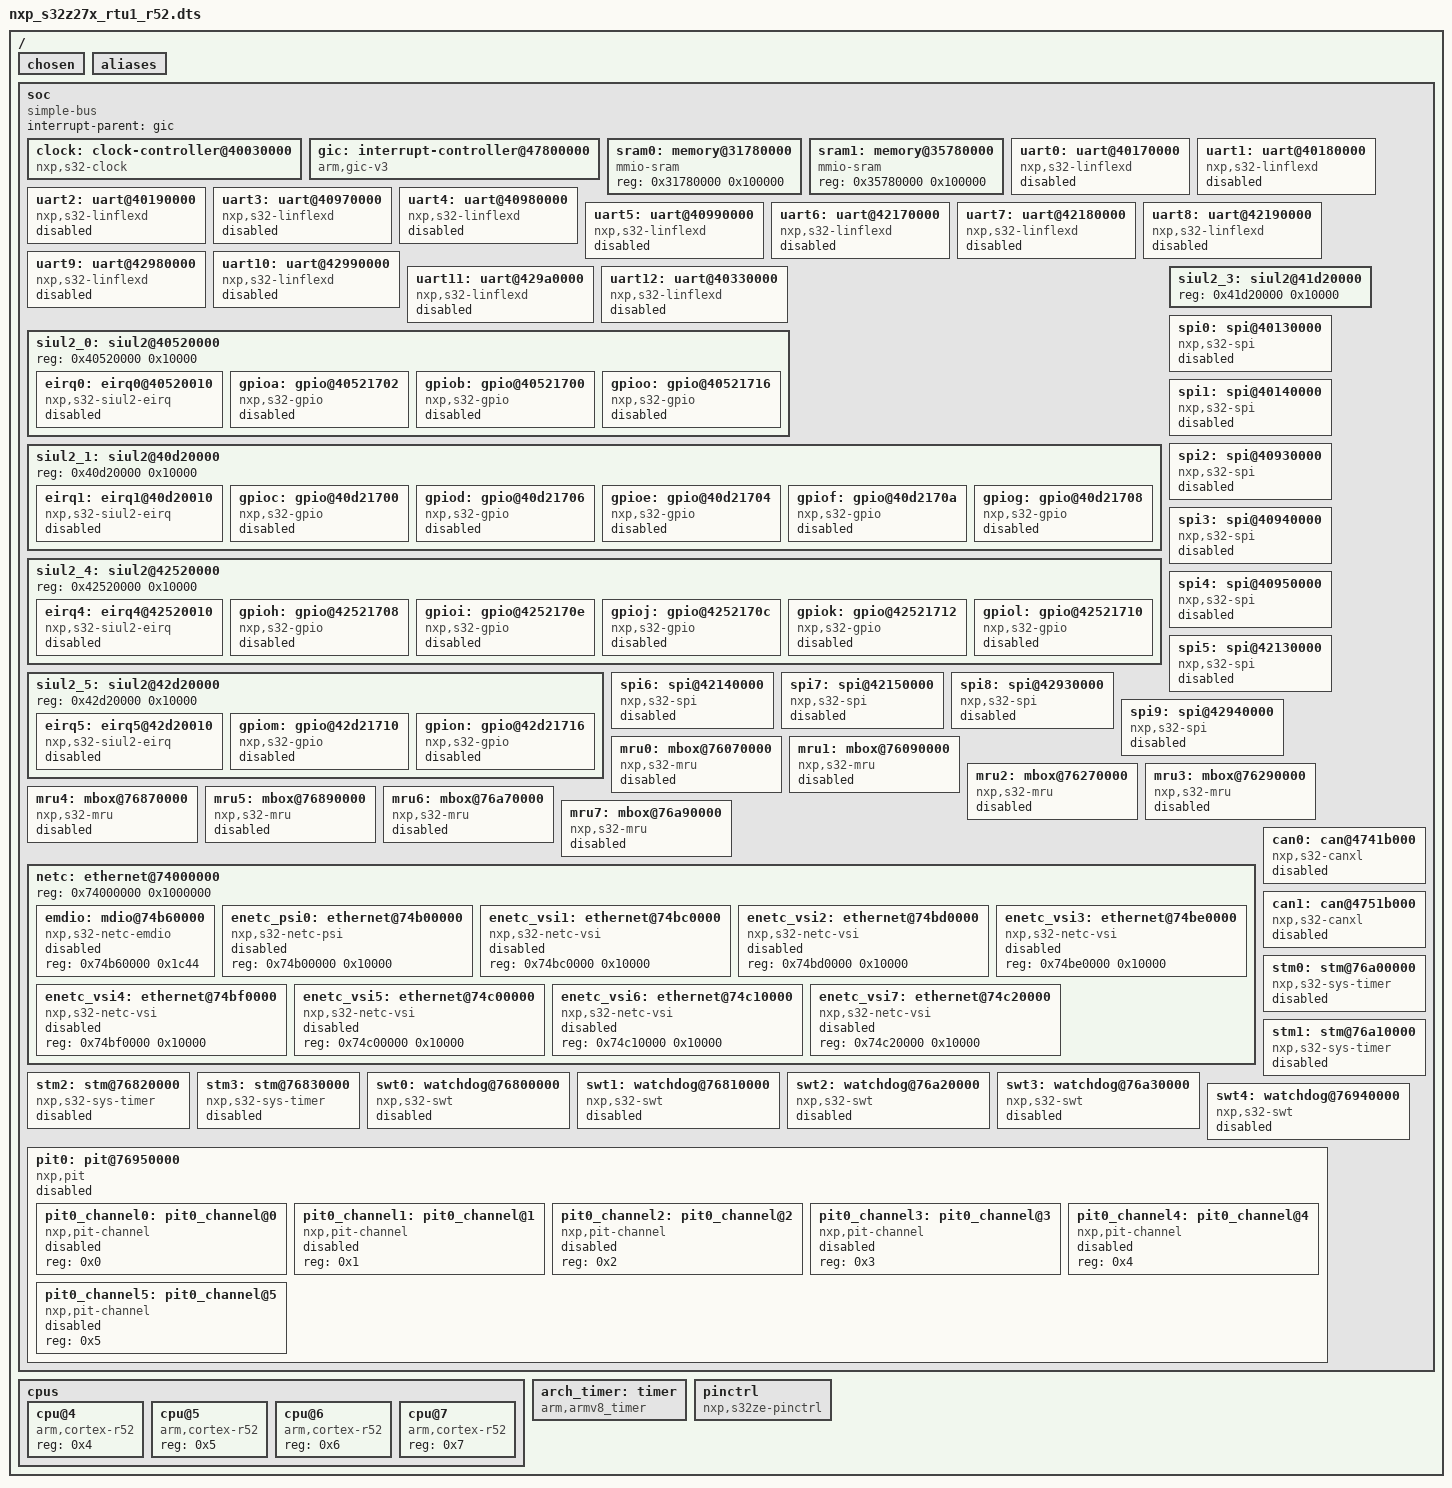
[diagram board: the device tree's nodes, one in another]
/dts-v1/;

/ {
	#address-cells = < 0x1 >;
	#size-cells = < 0x1 >;
	chosen {
	};
	aliases {
	};
	soc {
		#address-cells = < 0x1 >;
		#size-cells = < 0x1 >;
		compatible = "simple-bus";
		ranges;
		interrupt-parent = < &gic >;
		clock: clock-controller@40030000 {
			compatible = "nxp,s32-clock";
			reg = < 0x40030000 0x10000 >, < 0x40200000 0x10000 >, < 0x40210000 0x10000 >, < 0x40220000 0x10000 >, < 0x40260000 0x10000 >, < 0x40270000 0x10000 >, < 0x40830000 0x10000 >, < 0x41030000 0x10000 >, < 0x41830000 0x10000 >, < 0x42030000 0x10000 >, < 0x42830000 0x10000 >, < 0x44030000 0x10000 >, < 0x440a0000 0x10000 >;
			#clock-cells = < 0x1 >;
			status = "okay";
			phandle = < 0x6 >;
		};
		gic: interrupt-controller@47800000 {
			compatible = "arm,gic-v3", "arm,gic";
			reg = < 0x47800000 0x10000 >, < 0x47900000 0x80000 >;
			interrupt-controller;
			#interrupt-cells = < 0x4 >;
			status = "okay";
			phandle = < 0x1 >;
		};
		sram0: memory@31780000 {
			compatible = "mmio-sram";
			reg = < 0x31780000 0x100000 >;
		};
		sram1: memory@35780000 {
			compatible = "mmio-sram";
			reg = < 0x35780000 0x100000 >;
		};
		uart0: uart@40170000 {
			compatible = "nxp,s32-linflexd";
			reg = < 0x40170000 0x1000 >;
			interrupts = < 0x0 0xd4 0x2 0xa0 >;
			status = "disabled";
		};
		uart1: uart@40180000 {
			compatible = "nxp,s32-linflexd";
			reg = < 0x40180000 0x1000 >;
			interrupts = < 0x0 0xd5 0x2 0xa0 >;
			status = "disabled";
		};
		uart2: uart@40190000 {
			compatible = "nxp,s32-linflexd";
			reg = < 0x40190000 0x1000 >;
			interrupts = < 0x0 0xd6 0x2 0xa0 >;
			status = "disabled";
		};
		uart3: uart@40970000 {
			compatible = "nxp,s32-linflexd";
			reg = < 0x40970000 0x1000 >;
			interrupts = < 0x0 0xd7 0x2 0xa0 >;
			status = "disabled";
		};
		uart4: uart@40980000 {
			compatible = "nxp,s32-linflexd";
			reg = < 0x40980000 0x1000 >;
			interrupts = < 0x0 0xd8 0x2 0xa0 >;
			status = "disabled";
		};
		uart5: uart@40990000 {
			compatible = "nxp,s32-linflexd";
			reg = < 0x40990000 0x1000 >;
			interrupts = < 0x0 0xd9 0x2 0xa0 >;
			status = "disabled";
		};
		uart6: uart@42170000 {
			compatible = "nxp,s32-linflexd";
			reg = < 0x42170000 0x1000 >;
			interrupts = < 0x0 0xda 0x2 0xa0 >;
			status = "disabled";
		};
		uart7: uart@42180000 {
			compatible = "nxp,s32-linflexd";
			reg = < 0x42180000 0x1000 >;
			interrupts = < 0x0 0xdb 0x2 0xa0 >;
			status = "disabled";
		};
		uart8: uart@42190000 {
			compatible = "nxp,s32-linflexd";
			reg = < 0x42190000 0x1000 >;
			interrupts = < 0x0 0xdc 0x2 0xa0 >;
			status = "disabled";
		};
		uart9: uart@42980000 {
			compatible = "nxp,s32-linflexd";
			reg = < 0x42980000 0x1000 >;
			interrupts = < 0x0 0xdd 0x2 0xa0 >;
			status = "disabled";
		};
		uart10: uart@42990000 {
			compatible = "nxp,s32-linflexd";
			reg = < 0x42990000 0x1000 >;
			interrupts = < 0x0 0xde 0x2 0xa0 >;
			status = "disabled";
		};
		uart11: uart@429a0000 {
			compatible = "nxp,s32-linflexd";
			reg = < 0x429a0000 0x1000 >;
			interrupts = < 0x0 0xdf 0x2 0xa0 >;
			status = "disabled";
		};
		uart12: uart@40330000 {
			compatible = "nxp,s32-linflexd";
			reg = < 0x40330000 0x1000 >;
			interrupts = < 0x0 0xcd 0x2 0xa0 >;
			status = "disabled";
		};
		siul2_0: siul2@40520000 {
			reg = < 0x40520000 0x10000 >;
			#address-cells = < 0x1 >;
			#size-cells = < 0x1 >;
			eirq0: eirq0@40520010 {
				compatible = "nxp,s32-siul2-eirq";
				reg = < 0x40520010 0x4 >, < 0x40520018 0x4 >;
				reg-names = "disr0", "direr0";
				interrupts = < 0x0 0x202 0x2 0xa0 >;
				interrupt-controller;
				#interrupt-cells = < 0x2 >;
				status = "disabled";
				phandle = < 0x2 >;
			};
			gpioa: gpio@40521702 {
				compatible = "nxp,s32-gpio";
				reg = < 0x40521702 0x2 >, < 0x40520240 0x40 >;
				reg-names = "pgpdo", "mscr";
				interrupt-parent = < &eirq0 >;
				interrupts = < 0x1 0x1 >, < 0x3 0x0 >, < 0x5 0x2 >, < 0xc 0x3 >, < 0xd 0x4 >, < 0xe 0x5 >, < 0xf 0x6 >;
				gpio-controller;
				#gpio-cells = < 0x2 >;
				ngpios = < 0x10 >;
				status = "disabled";
			};
			gpiob: gpio@40521700 {
				compatible = "nxp,s32-gpio";
				reg = < 0x40521700 0x2 >, < 0x40520280 0x40 >;
				reg-names = "pgpdo", "mscr";
				interrupt-parent = < &eirq0 >;
				interrupts = < 0x0 0x7 >;
				gpio-controller;
				#gpio-cells = < 0x2 >;
				ngpios = < 0xf >;
				status = "disabled";
			};
			gpioo: gpio@40521716 {
				compatible = "nxp,s32-gpio";
				reg = < 0x40521716 0x2 >, < 0x405204c0 0x40 >;
				reg-names = "pgpdo", "mscr";
				gpio-controller;
				#gpio-cells = < 0x2 >;
				ngpios = < 0xe >;
				gpio-reserved-ranges = < 0x0 0xa >;
				status = "disabled";
			};
		};
		siul2_1: siul2@40d20000 {
			reg = < 0x40d20000 0x10000 >;
			#address-cells = < 0x1 >;
			#size-cells = < 0x1 >;
			eirq1: eirq1@40d20010 {
				compatible = "nxp,s32-siul2-eirq";
				reg = < 0x40d20010 0x4 >, < 0x40d20018 0x4 >;
				reg-names = "disr0", "direr0";
				interrupts = < 0x0 0x203 0x2 0xa0 >;
				interrupt-controller;
				#interrupt-cells = < 0x2 >;
				status = "disabled";
				phandle = < 0x3 >;
			};
			gpioc: gpio@40d21700 {
				compatible = "nxp,s32-gpio";
				reg = < 0x40d21700 0x2 >, < 0x40d20280 0x40 >;
				reg-names = "pgpdo", "mscr";
				interrupt-parent = < &eirq1 >;
				interrupts = < 0x3 0x0 >, < 0x5 0x1 >;
				gpio-controller;
				#gpio-cells = < 0x2 >;
				ngpios = < 0x10 >;
				gpio-reserved-ranges = < 0x0 0xf >;
				status = "disabled";
			};
			gpiod: gpio@40d21706 {
				compatible = "nxp,s32-gpio";
				reg = < 0x40d21706 0x2 >, < 0x40d202c0 0x40 >;
				reg-names = "pgpdo", "mscr";
				gpio-controller;
				#gpio-cells = < 0x2 >;
				ngpios = < 0x10 >;
				status = "disabled";
			};
			gpioe: gpio@40d21704 {
				compatible = "nxp,s32-gpio";
				reg = < 0x40d21704 0x2 >, < 0x40d20300 0x40 >;
				reg-names = "pgpdo", "mscr";
				gpio-controller;
				#gpio-cells = < 0x2 >;
				ngpios = < 0x10 >;
				status = "disabled";
			};
			gpiof: gpio@40d2170a {
				compatible = "nxp,s32-gpio";
				reg = < 0x40d2170a 0x2 >, < 0x40d20340 0x40 >;
				reg-names = "pgpdo", "mscr";
				gpio-controller;
				#gpio-cells = < 0x2 >;
				ngpios = < 0x10 >;
				status = "disabled";
			};
			gpiog: gpio@40d21708 {
				compatible = "nxp,s32-gpio";
				reg = < 0x40d21708 0x2 >, < 0x40d20380 0x40 >;
				reg-names = "pgpdo", "mscr";
				interrupt-parent = < &eirq1 >;
				interrupts = < 0x0 0x2 >, < 0x1 0x3 >, < 0x4 0x4 >, < 0x5 0x5 >, < 0xa 0x6 >, < 0xb 0x7 >;
				gpio-controller;
				#gpio-cells = < 0x2 >;
				ngpios = < 0xc >;
				status = "disabled";
			};
		};
		siul2_3: siul2@41d20000 {
			reg = < 0x41d20000 0x10000 >;
		};
		siul2_4: siul2@42520000 {
			reg = < 0x42520000 0x10000 >;
			#address-cells = < 0x1 >;
			#size-cells = < 0x1 >;
			eirq4: eirq4@42520010 {
				compatible = "nxp,s32-siul2-eirq";
				reg = < 0x42520010 0x4 >, < 0x42520018 0x4 >;
				reg-names = "disr0", "direr0";
				interrupts = < 0x0 0x204 0x2 0xa0 >;
				interrupt-controller;
				#interrupt-cells = < 0x2 >;
				status = "disabled";
				phandle = < 0x4 >;
			};
			gpioh: gpio@42521708 {
				compatible = "nxp,s32-gpio";
				reg = < 0x42521708 0x2 >, < 0x42520380 0x40 >;
				reg-names = "pgpdo", "mscr";
				gpio-controller;
				#gpio-cells = < 0x2 >;
				ngpios = < 0x10 >;
				gpio-reserved-ranges = < 0x0 0xc >;
				status = "disabled";
			};
			gpioi: gpio@4252170e {
				compatible = "nxp,s32-gpio";
				reg = < 0x4252170e 0x2 >, < 0x425203c0 0x40 >;
				reg-names = "pgpdo", "mscr";
				interrupt-parent = < &eirq4 >;
				interrupts = < 0xb 0x0 >, < 0xd 0x1 >;
				gpio-controller;
				#gpio-cells = < 0x2 >;
				ngpios = < 0x10 >;
				status = "disabled";
			};
			gpioj: gpio@4252170c {
				compatible = "nxp,s32-gpio";
				reg = < 0x4252170c 0x2 >, < 0x42520400 0x40 >;
				reg-names = "pgpdo", "mscr";
				interrupt-parent = < &eirq4 >;
				interrupts = < 0xc 0x2 >;
				gpio-controller;
				#gpio-cells = < 0x2 >;
				ngpios = < 0x10 >;
				status = "disabled";
			};
			gpiok: gpio@42521712 {
				compatible = "nxp,s32-gpio";
				reg = < 0x42521712 0x2 >, < 0x42520440 0x40 >;
				reg-names = "pgpdo", "mscr";
				interrupt-parent = < &eirq4 >;
				interrupts = < 0x4 0x3 >, < 0x6 0x4 >, < 0x9 0x5 >, < 0xb 0x6 >, < 0xd 0x7 >;
				gpio-controller;
				#gpio-cells = < 0x2 >;
				ngpios = < 0x10 >;
				status = "disabled";
			};
			gpiol: gpio@42521710 {
				compatible = "nxp,s32-gpio";
				reg = < 0x42521710 0x2 >, < 0x42520480 0x40 >;
				reg-names = "pgpdo", "mscr";
				gpio-controller;
				#gpio-cells = < 0x2 >;
				ngpios = < 0x2 >;
				status = "disabled";
			};
		};
		siul2_5: siul2@42d20000 {
			reg = < 0x42d20000 0x10000 >;
			#address-cells = < 0x1 >;
			#size-cells = < 0x1 >;
			eirq5: eirq5@42d20010 {
				compatible = "nxp,s32-siul2-eirq";
				reg = < 0x42d20010 0x4 >, < 0x42d20018 0x4 >;
				reg-names = "disr0", "direr0";
				interrupts = < 0x0 0x205 0x2 0xa0 >;
				interrupt-controller;
				#interrupt-cells = < 0x2 >;
				status = "disabled";
				phandle = < 0x5 >;
			};
			gpiom: gpio@42d21710 {
				compatible = "nxp,s32-gpio";
				reg = < 0x42d21710 0x2 >, < 0x42d20480 0x40 >;
				reg-names = "pgpdo", "mscr";
				interrupt-parent = < &eirq5 >;
				interrupts = < 0x1 0x0 >, < 0x3 0x1 >, < 0x5 0x2 >, < 0x7 0x3 >;
				gpio-controller;
				#gpio-cells = < 0x2 >;
				ngpios = < 0x10 >;
				gpio-reserved-ranges = < 0x0 0x2 >;
				status = "disabled";
			};
			gpion: gpio@42d21716 {
				compatible = "nxp,s32-gpio";
				reg = < 0x42d21716 0x2 >, < 0x42d204c0 0x40 >;
				reg-names = "pgpdo", "mscr";
				interrupt-parent = < &eirq5 >;
				interrupts = < 0x0 0x4 >, < 0x2 0x5 >, < 0x5 0x6 >, < 0x6 0x7 >;
				gpio-controller;
				#gpio-cells = < 0x2 >;
				ngpios = < 0xa >;
				status = "disabled";
			};
		};
		spi0: spi@40130000 {
			compatible = "nxp,s32-spi";
			reg = < 0x40130000 0x10000 >;
			interrupts = < 0x0 0xbf 0x2 0xa0 >;
			clocks = < &clock 0x110 >;
			num-cs = < 0x5 >;
			#address-cells = < 0x1 >;
			#size-cells = < 0x0 >;
			status = "disabled";
		};
		spi1: spi@40140000 {
			compatible = "nxp,s32-spi";
			reg = < 0x40140000 0x10000 >;
			interrupts = < 0x0 0xc0 0x2 0xa0 >;
			clocks = < &clock 0x111 >;
			num-cs = < 0x5 >;
			#address-cells = < 0x1 >;
			#size-cells = < 0x0 >;
			status = "disabled";
		};
		spi2: spi@40930000 {
			compatible = "nxp,s32-spi";
			reg = < 0x40930000 0x10000 >;
			interrupts = < 0x0 0xc1 0x2 0xa0 >;
			clocks = < &clock 0x113 >;
			num-cs = < 0x5 >;
			#address-cells = < 0x1 >;
			#size-cells = < 0x0 >;
			status = "disabled";
		};
		spi3: spi@40940000 {
			compatible = "nxp,s32-spi";
			reg = < 0x40940000 0x10000 >;
			interrupts = < 0x0 0xc2 0x2 0xa0 >;
			clocks = < &clock 0x114 >;
			num-cs = < 0x5 >;
			#address-cells = < 0x1 >;
			#size-cells = < 0x0 >;
			status = "disabled";
		};
		spi4: spi@40950000 {
			compatible = "nxp,s32-spi";
			reg = < 0x40950000 0x10000 >;
			interrupts = < 0x0 0xc3 0x2 0xa0 >;
			clocks = < &clock 0x115 >;
			num-cs = < 0x5 >;
			#address-cells = < 0x1 >;
			#size-cells = < 0x0 >;
			status = "disabled";
		};
		spi5: spi@42130000 {
			compatible = "nxp,s32-spi";
			reg = < 0x42130000 0x10000 >;
			interrupts = < 0x0 0xc4 0x2 0xa0 >;
			clocks = < &clock 0x117 >;
			num-cs = < 0x5 >;
			#address-cells = < 0x1 >;
			#size-cells = < 0x0 >;
			status = "disabled";
		};
		spi6: spi@42140000 {
			compatible = "nxp,s32-spi";
			reg = < 0x42140000 0x10000 >;
			interrupts = < 0x0 0xc5 0x2 0xa0 >;
			clocks = < &clock 0x118 >;
			num-cs = < 0x5 >;
			#address-cells = < 0x1 >;
			#size-cells = < 0x0 >;
			status = "disabled";
		};
		spi7: spi@42150000 {
			compatible = "nxp,s32-spi";
			reg = < 0x42150000 0x10000 >;
			interrupts = < 0x0 0xc6 0x2 0xa0 >;
			clocks = < &clock 0x119 >;
			num-cs = < 0x5 >;
			#address-cells = < 0x1 >;
			#size-cells = < 0x0 >;
			status = "disabled";
		};
		spi8: spi@42930000 {
			compatible = "nxp,s32-spi";
			reg = < 0x42930000 0x10000 >;
			interrupts = < 0x0 0xc7 0x2 0xa0 >;
			clocks = < &clock 0x11b >;
			num-cs = < 0x5 >;
			#address-cells = < 0x1 >;
			#size-cells = < 0x0 >;
			status = "disabled";
		};
		spi9: spi@42940000 {
			compatible = "nxp,s32-spi";
			reg = < 0x42940000 0x10000 >;
			interrupts = < 0x0 0xc8 0x2 0xa0 >;
			clocks = < &clock 0x11c >;
			num-cs = < 0x5 >;
			#address-cells = < 0x1 >;
			#size-cells = < 0x0 >;
			status = "disabled";
		};
		mru0: mbox@76070000 {
			compatible = "nxp,s32-mru";
			reg = < 0x76070000 0x10000 >;
			interrupts = < 0x1 0x1 0x2 0xa0 >;
			#mbox-cells = < 0x1 >;
			status = "disabled";
		};
		mru1: mbox@76090000 {
			compatible = "nxp,s32-mru";
			reg = < 0x76090000 0x10000 >;
			interrupts = < 0x1 0x1 0x2 0xa0 >;
			#mbox-cells = < 0x1 >;
			status = "disabled";
		};
		mru2: mbox@76270000 {
			compatible = "nxp,s32-mru";
			reg = < 0x76270000 0x10000 >;
			interrupts = < 0x1 0x1 0x2 0xa0 >;
			#mbox-cells = < 0x1 >;
			status = "disabled";
		};
		mru3: mbox@76290000 {
			compatible = "nxp,s32-mru";
			reg = < 0x76290000 0x10000 >;
			interrupts = < 0x1 0x1 0x2 0xa0 >;
			#mbox-cells = < 0x1 >;
			status = "disabled";
		};
		mru4: mbox@76870000 {
			compatible = "nxp,s32-mru";
			reg = < 0x76870000 0x10000 >;
			interrupts = < 0x1 0x1 0x2 0xa0 >;
			#mbox-cells = < 0x1 >;
			status = "disabled";
		};
		mru5: mbox@76890000 {
			compatible = "nxp,s32-mru";
			reg = < 0x76890000 0x10000 >;
			interrupts = < 0x1 0x1 0x2 0xa0 >;
			#mbox-cells = < 0x1 >;
			status = "disabled";
		};
		mru6: mbox@76a70000 {
			compatible = "nxp,s32-mru";
			reg = < 0x76a70000 0x10000 >;
			interrupts = < 0x1 0x1 0x2 0xa0 >;
			#mbox-cells = < 0x1 >;
			status = "disabled";
		};
		mru7: mbox@76a90000 {
			compatible = "nxp,s32-mru";
			reg = < 0x76a90000 0x10000 >;
			interrupts = < 0x1 0x1 0x2 0xa0 >;
			#mbox-cells = < 0x1 >;
			status = "disabled";
		};
		netc: ethernet@74000000 {
			reg = < 0x74000000 0x1000000 >;
			#address-cells = < 0x1 >;
			#size-cells = < 0x1 >;
			ranges;
			emdio: mdio@74b60000 {
				compatible = "nxp,s32-netc-emdio";
				reg = < 0x74b60000 0x1c44 >;
				status = "disabled";
				#address-cells = < 0x1 >;
				#size-cells = < 0x0 >;
			};
			enetc_psi0: ethernet@74b00000 {
				compatible = "nxp,s32-netc-psi";
				reg = < 0x74b00000 0x10000 >;
				status = "disabled";
			};
			enetc_vsi1: ethernet@74bc0000 {
				compatible = "nxp,s32-netc-vsi";
				reg = < 0x74bc0000 0x10000 >;
				status = "disabled";
			};
			enetc_vsi2: ethernet@74bd0000 {
				compatible = "nxp,s32-netc-vsi";
				reg = < 0x74bd0000 0x10000 >;
				status = "disabled";
			};
			enetc_vsi3: ethernet@74be0000 {
				compatible = "nxp,s32-netc-vsi";
				reg = < 0x74be0000 0x10000 >;
				status = "disabled";
			};
			enetc_vsi4: ethernet@74bf0000 {
				compatible = "nxp,s32-netc-vsi";
				reg = < 0x74bf0000 0x10000 >;
				status = "disabled";
			};
			enetc_vsi5: ethernet@74c00000 {
				compatible = "nxp,s32-netc-vsi";
				reg = < 0x74c00000 0x10000 >;
				status = "disabled";
			};
			enetc_vsi6: ethernet@74c10000 {
				compatible = "nxp,s32-netc-vsi";
				reg = < 0x74c10000 0x10000 >;
				status = "disabled";
			};
			enetc_vsi7: ethernet@74c20000 {
				compatible = "nxp,s32-netc-vsi";
				reg = < 0x74c20000 0x10000 >;
				status = "disabled";
			};
		};
		can0: can@4741b000 {
			compatible = "nxp,s32-canxl";
			reg = < 0x4741b000 0x1000 >, < 0x47423000 0x1000 >, < 0x47425000 0x1000 >;
			reg-names = "sic", "rx_fifo", "rx_fifo_ctrl";
			status = "disabled";
			interrupts = < 0x0 0xe0 0x2 0xa0 >, < 0x0 0xe1 0x2 0xa0 >;
			interrupt-names = "rx_tx", "error";
			clocks = < &clock 0xe7 >;
		};
		can1: can@4751b000 {
			compatible = "nxp,s32-canxl";
			reg = < 0x4751b000 0x1000 >, < 0x47523000 0x1000 >, < 0x47525000 0x1000 >;
			reg-names = "sic", "rx_fifo", "rx_fifo_ctrl";
			status = "disabled";
			interrupts = < 0x0 0xe2 0x2 0xa0 >, < 0x0 0xe3 0x2 0xa0 >;
			interrupt-names = "rx_tx", "error";
			clocks = < &clock 0xe7 >;
		};
		stm0: stm@76a00000 {
			compatible = "nxp,s32-sys-timer";
			reg = < 0x76a00000 0x10000 >;
			interrupts = < 0x0 0xd 0x2 0xa0 >;
			clocks = < &clock 0x104 >;
			status = "disabled";
		};
		stm1: stm@76a10000 {
			compatible = "nxp,s32-sys-timer";
			reg = < 0x76a10000 0x10000 >;
			interrupts = < 0x0 0xe 0x2 0xa0 >;
			clocks = < &clock 0x104 >;
			status = "disabled";
		};
		stm2: stm@76820000 {
			compatible = "nxp,s32-sys-timer";
			reg = < 0x76820000 0x10000 >;
			interrupts = < 0x0 0xf 0x2 0xa0 >;
			clocks = < &clock 0x104 >;
			status = "disabled";
		};
		stm3: stm@76830000 {
			compatible = "nxp,s32-sys-timer";
			reg = < 0x76830000 0x10000 >;
			interrupts = < 0x0 0x10 0x2 0xa0 >;
			clocks = < &clock 0x104 >;
			status = "disabled";
		};
		swt0: watchdog@76800000 {
			compatible = "nxp,s32-swt";
			reg = < 0x76800000 0x10000 >;
			interrupts = < 0x0 0x8 0x2 0xa0 >;
			clocks = < &clock 0x1 >;
			status = "disabled";
		};
		swt1: watchdog@76810000 {
			compatible = "nxp,s32-swt";
			reg = < 0x76810000 0x10000 >;
			interrupts = < 0x0 0x9 0x2 0xa0 >;
			clocks = < &clock 0x1 >;
			status = "disabled";
		};
		swt2: watchdog@76a20000 {
			compatible = "nxp,s32-swt";
			reg = < 0x76a20000 0x10000 >;
			interrupts = < 0x0 0xa 0x2 0xa0 >;
			clocks = < &clock 0x1 >;
			status = "disabled";
		};
		swt3: watchdog@76a30000 {
			compatible = "nxp,s32-swt";
			reg = < 0x76a30000 0x10000 >;
			interrupts = < 0x0 0xb 0x2 0xa0 >;
			clocks = < &clock 0x1 >;
			status = "disabled";
		};
		swt4: watchdog@76940000 {
			compatible = "nxp,s32-swt";
			reg = < 0x76940000 0x10000 >;
			interrupts = < 0x0 0xc 0x2 0xa0 >;
			clocks = < &clock 0x1 >;
			status = "disabled";
		};
		pit0: pit@76950000 {
			compatible = "nxp,pit";
			reg = < 0x76950000 0x10000 >;
			interrupts = < 0x0 0x13 0x2 0xa0 >;
			clocks = < &clock 0xc2 >;
			max-load-value = < 0xffffff >;
			status = "disabled";
			#address-cells = < 0x1 >;
			#size-cells = < 0x0 >;
			pit0_channel0: pit0_channel@0 {
				compatible = "nxp,pit-channel";
				reg = < 0x0 >;
				status = "disabled";
			};
			pit0_channel1: pit0_channel@1 {
				compatible = "nxp,pit-channel";
				reg = < 0x1 >;
				status = "disabled";
			};
			pit0_channel2: pit0_channel@2 {
				compatible = "nxp,pit-channel";
				reg = < 0x2 >;
				status = "disabled";
			};
			pit0_channel3: pit0_channel@3 {
				compatible = "nxp,pit-channel";
				reg = < 0x3 >;
				status = "disabled";
			};
			pit0_channel4: pit0_channel@4 {
				compatible = "nxp,pit-channel";
				reg = < 0x4 >;
				status = "disabled";
			};
			pit0_channel5: pit0_channel@5 {
				compatible = "nxp,pit-channel";
				reg = < 0x5 >;
				status = "disabled";
			};
		};
	};
	cpus {
		#address-cells = < 0x1 >;
		#size-cells = < 0x0 >;
		cpu@4 {
			device_type = "cpu";
			compatible = "arm,cortex-r52";
			reg = < 0x4 >;
		};
		cpu@5 {
			device_type = "cpu";
			compatible = "arm,cortex-r52";
			reg = < 0x5 >;
		};
		cpu@6 {
			device_type = "cpu";
			compatible = "arm,cortex-r52";
			reg = < 0x6 >;
		};
		cpu@7 {
			device_type = "cpu";
			compatible = "arm,cortex-r52";
			reg = < 0x7 >;
		};
	};
	arch_timer: timer {
		compatible = "arm,armv8_timer";
		interrupts = < 0x1 0xd 0x2 0xa0 >, < 0x1 0xe 0x2 0xa0 >, < 0x1 0xb 0x2 0xa0 >, < 0x1 0xa 0x2 0xa0 >;
		interrupt-parent = < &gic >;
	};
	pinctrl: pinctrl {
		compatible = "nxp,s32ze-pinctrl";
		status = "okay";
	};
};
